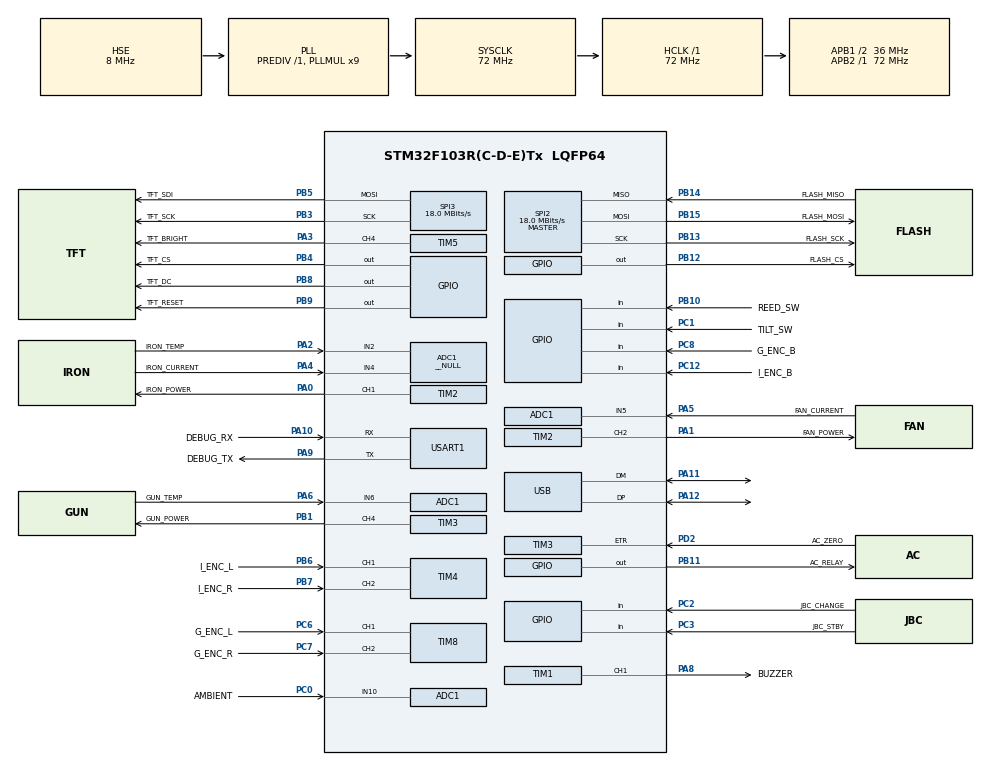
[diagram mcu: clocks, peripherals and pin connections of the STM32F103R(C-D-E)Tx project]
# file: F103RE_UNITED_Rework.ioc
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ADC1.Channel-0\#ChannelRegularConversion=ADC_CHANNEL_4
ADC1.Channel-1\#ChannelRegularConversion=ADC_CHANNEL_5
ADC1.Channel-2\#ChannelRegularConversion=ADC_CHANNEL_2
ADC1.Channel-6\#ChannelRegularConversion=ADC_CHANNEL_6
ADC1.Channel-7\#ChannelRegularConversion=ADC_CHANNEL_10
ADC1.ContinuousConvMode=ENABLE
ADC1.Mode=__NULL
ADC1.NbrOfConversion=5
ADC1.NbrOfConversionFlag=1
ADC1.Rank-0\#ChannelRegularConversion=1
ADC1.Rank-1\#ChannelRegularConversion=2
ADC1.Rank-2\#ChannelRegularConversion=3
ADC1.Rank-6\#ChannelRegularConversion=4
ADC1.Rank-7\#ChannelRegularConversion=5
ADC1.SamplingTime-0\#ChannelRegularConversion=ADC_SAMPLETIME_71CYCLES_5
ADC1.SamplingTime-1\#ChannelRegularConversion=ADC_SAMPLETIME_71CYCLES_5
ADC1.SamplingTime-2\#ChannelRegularConversion=ADC_SAMPLETIME_239CYCLES_5
ADC1.SamplingTime-6\#ChannelRegularConversion=ADC_SAMPLETIME_239CYCLES_5
ADC1.SamplingTime-7\#ChannelRegularConversion=ADC_SAMPLETIME_239CYCLES_5
ADC1.master=1
Dma.ADC1.0.Direction=DMA_PERIPH_TO_MEMORY
Dma.ADC1.0.Instance=DMA1_Channel1
Dma.ADC1.0.MemDataAlignment=DMA_MDATAALIGN_HALFWORD
Dma.ADC1.0.MemInc=DMA_MINC_ENABLE
Dma.ADC1.0.Mode=DMA_NORMAL
Dma.ADC1.0.PeriphDataAlignment=DMA_PDATAALIGN_HALFWORD
Dma.ADC1.0.PeriphInc=DMA_PINC_DISABLE
Dma.ADC1.0.Priority=DMA_PRIORITY_LOW
Dma.Request0=ADC1
Dma.Request1=SPI3_TX
Dma.Request2=TIM3_CH4/UP
Dma.SPI3_TX.1.Direction=DMA_MEMORY_TO_PERIPH
Dma.SPI3_TX.1.Instance=DMA2_Channel2
Dma.SPI3_TX.1.MemDataAlignment=DMA_MDATAALIGN_BYTE
Dma.SPI3_TX.1.MemInc=DMA_MINC_ENABLE
Dma.SPI3_TX.1.Mode=DMA_NORMAL
Dma.SPI3_TX.1.PeriphDataAlignment=DMA_PDATAALIGN_BYTE
Dma.SPI3_TX.1.PeriphInc=DMA_PINC_DISABLE
Dma.SPI3_TX.1.Priority=DMA_PRIORITY_LOW
Dma.TIM3_CH4/UP.2.Direction=DMA_MEMORY_TO_PERIPH
Dma.TIM3_CH4/UP.2.Instance=DMA1_Channel3
Dma.TIM3_CH4/UP.2.MemDataAlignment=DMA_MDATAALIGN_BYTE
Dma.TIM3_CH4/UP.2.MemInc=DMA_MINC_ENABLE
Dma.TIM3_CH4/UP.2.Mode=DMA_CIRCULAR
Dma.TIM3_CH4/UP.2.PeriphDataAlignment=DMA_PDATAALIGN_HALFWORD
Dma.TIM3_CH4/UP.2.PeriphInc=DMA_PINC_DISABLE
Dma.TIM3_CH4/UP.2.Priority=DMA_PRIORITY_LOW
Mcu.Family=STM32F1
Mcu.Name=STM32F103R(C-D-E)Tx
Mcu.Package=LQFP64
NVIC.DMA1_Channel1_IRQn=true\:0\:0\:false\:false\:true\:false\:true\:true
NVIC.DMA1_Channel3_IRQn=true\:0\:0\:false\:false\:true\:false\:true\:true
NVIC.DMA2_Channel2_IRQn=true\:0\:0\:false\:false\:true\:false\:true\:true
NVIC.PriorityGroup=NVIC_PRIORITYGROUP_4
NVIC.TIM2_IRQn=true\:0\:0\:false\:false\:true\:true\:true\:true
NVIC.TIM3_IRQn=true\:0\:0\:false\:false\:true\:true\:true\:true
NVIC.TIM6_IRQn=true\:0\:0\:false\:false\:true\:true\:true\:true
NVIC.USB_LP_CAN1_RX0_IRQn=true\:0\:0\:false\:false\:true\:false\:true\:true
PA0-WKUP.GPIO_Label=IRON_POWER
PA0-WKUP.Signal=S_TIM2_CH1_ETR
PA1.GPIO_Label=FAN_POWER
PA1.Signal=S_TIM2_CH2
PA10.GPIO_Label=DEBUG_RX
PA10.Mode=Asynchronous
PA10.Signal=USART1_RX
PA11.Mode=Device
PA11.Signal=USB_DM
PA12.Mode=Device
PA12.Signal=USB_DP
PA13.Mode=Serial_Wire
PA13.Signal=SYS_JTMS-SWDIO
PA14.Mode=Serial_Wire
PA14.Signal=SYS_JTCK-SWCLK
PA2.GPIO_Label=IRON_TEMP
PA2.Signal=ADCx_IN2
PA3.GPIO_Label=TFT_BRIGHT
PA3.Signal=S_TIM5_CH4
PA4.GPIO_Label=IRON_CURRENT
PA4.Signal=ADCx_IN4
PA5.GPIO_Label=FAN_CURRENT
PA5.Signal=ADCx_IN5
PA6.GPIO_Label=GUN_TEMP
PA6.Signal=ADCx_IN6
PA8.GPIO_Label=BUZZER
PA8.Signal=S_TIM1_CH1
PA9.GPIO_Label=DEBUG_TX
PA9.Mode=Asynchronous
PA9.Signal=USART1_TX
PB1.GPIO_Label=GUN_POWER
PB1.Signal=S_TIM3_CH4
PB10.GPIO_Label=REED_SW
PB10.Signal=GPIO_Input
PB11.GPIO_Label=AC_RELAY
PB11.Signal=GPIO_Output
PB12.GPIO_Label=FLASH_CS
PB12.PinState=GPIO_PIN_SET
PB12.Signal=GPIO_Output
PB13.GPIO_Label=FLASH_SCK
PB13.Mode=Full_Duplex_Master
PB13.Signal=SPI2_SCK
PB14.GPIO_Label=FLASH_MISO
PB14.Mode=Full_Duplex_Master
PB14.Signal=SPI2_MISO
PB15.GPIO_Label=FLASH_MOSI
PB15.Mode=Full_Duplex_Master
PB15.Signal=SPI2_MOSI
PB3.GPIO_Label=TFT_SCK
PB3.Mode=TX_Only_Simplex_Unidirect_Master
PB3.Signal=SPI3_SCK
PB4.GPIO_Label=TFT_CS
PB4.PinState=GPIO_PIN_SET
PB4.Signal=GPIO_Output
PB5.GPIO_Label=TFT_SDI
PB5.Mode=TX_Only_Simplex_Unidirect_Master
PB5.Signal=SPI3_MOSI
PB6.GPIO_Label=I_ENC_L
PB6.Signal=S_TIM4_CH1
PB7.GPIO_Label=I_ENC_R
PB7.Signal=S_TIM4_CH2
PB8.GPIO_Label=TFT_DC
PB8.Signal=GPIO_Output
PB9.GPIO_Label=TFT_RESET
PB9.PinState=GPIO_PIN_SET
PB9.Signal=GPIO_Output
PC0.GPIO_Label=AMBIENT
PC0.Signal=ADCx_IN10
PC1.GPIO_Label=TILT_SW
PC1.Signal=GPIO_Input
PC12.GPIO_Label=I_ENC_B
PC12.Signal=GPIO_Input
PC2.GPIO_Label=JBC_CHANGE
PC2.Signal=GPIO_Input
PC3.GPIO_Label=JBC_STBY
PC3.Signal=GPIO_Input
PC6.GPIO_Label=G_ENC_L
PC6.Signal=S_TIM8_CH1
PC7.GPIO_Label=G_ENC_R
PC7.Signal=S_TIM8_CH2
PC8.GPIO_Label=G_ENC_B
PC8.Signal=GPIO_Input
PD0-OSC_IN.Mode=HSE-External-Oscillator
PD0-OSC_IN.Signal=RCC_OSC_IN
PD1-OSC_OUT.Mode=HSE-External-Oscillator
PD1-OSC_OUT.Signal=RCC_OSC_OUT
PD2.GPIO_Label=AC_ZERO
PD2.Signal=S_TIM3_ETR
ProjectManager.HeapSize=0x200
ProjectManager.StackSize=0x400
ProjectManager.TargetToolchain=STM32CubeIDE
RCC.ADCPresc=RCC_ADCPCLK2_DIV6
RCC.AHBFreq_Value=72000000
RCC.APB1CLKDivider=RCC_HCLK_DIV2
RCC.APB1Freq_Value=36000000
RCC.APB1TimFreq_Value=72000000
RCC.APB2Freq_Value=72000000
RCC.APB2TimFreq_Value=72000000
RCC.HCLKFreq_Value=72000000
RCC.PLLMUL=RCC_PLL_MUL9
RCC.PLLSourceVirtual=RCC_PLLSOURCE_HSE
RCC.SYSCLKFreq_VALUE=72000000
RCC.SYSCLKSource=RCC_SYSCLKSOURCE_PLLCLK
RCC.USBFreq_Value=48000000
RCC.USBPrescaler=RCC_USBCLKSOURCE_PLL_DIV1_5
SH.ADCx_IN10.0=ADC1_IN10,IN10
SH.ADCx_IN2.0=ADC1_IN2,IN2
SH.ADCx_IN4.0=ADC1_IN4,IN4
SH.ADCx_IN5.0=ADC1_IN5,IN5
SH.ADCx_IN6.0=ADC1_IN6,IN6
SH.S_TIM1_CH1.0=TIM1_CH1,PWM Generation1 CH1
SH.S_TIM2_CH1_ETR.0=TIM2_CH1,PWM Generation1 CH1
SH.S_TIM2_CH2.0=TIM2_CH2,PWM Generation2 CH2
SH.S_TIM3_CH4.0=TIM3_CH4,PWM Generation4 CH4
SH.S_TIM3_ETR.0=TIM3_ETR,TriggerSource_ETR
SH.S_TIM4_CH1.0=TIM4_CH1,Encoder_Interface
SH.S_TIM4_CH2.0=TIM4_CH2,Encoder_Interface
SH.S_TIM5_CH4.0=TIM5_CH4,PWM Generation4 CH4
SH.S_TIM8_CH1.0=TIM8_CH1,Encoder_Interface
SH.S_TIM8_CH2.0=TIM8_CH2,Encoder_Interface
SPI2.CalculateBaudRate=18.0 MBits/s
SPI2.Direction=SPI_DIRECTION_2LINES
SPI2.Mode=SPI_MODE_MASTER
SPI2.VirtualType=VM_MASTER
SPI3.CalculateBaudRate=18.0 MBits/s
SPI3.Direction=SPI_DIRECTION_2LINES
SPI3.Mode=SPI_MODE_MASTER
SPI3.VirtualType=VM_MASTER
TIM1.Channel-PWM\ Generation1\ CH1=TIM_CHANNEL_1
TIM1.Prescaler=71
TIM2.Channel-Output\ Compare3\ No\ Output=TIM_CHANNEL_3
TIM2.Channel-Output\ Compare4\ No\ Output=TIM_CHANNEL_4
TIM2.Channel-PWM\ Generation1\ CH1=TIM_CHANNEL_1
TIM2.Channel-PWM\ Generation2\ CH2=TIM_CHANNEL_2
TIM2.Period=1999
TIM2.Prescaler=719
TIM2.Pulse-Output\ Compare3\ No\ Output=1
TIM2.Pulse-Output\ Compare4\ No\ Output=1970
TIM3.Channel-PWM\ Generation4\ CH4=TIM_CHANNEL_4
TIM3.OCMode_PWM-PWM\ Generation4\ CH4=TIM_OCMODE_PWM1
TIM3.Period=255
TIM3.Prescaler=7199
TIM3.Slave_TriggerFilter=7
TIM5.Channel-PWM\ Generation4\ CH4=TIM_CHANNEL_4
TIM5.OCPolarity_4=TIM_OCPOLARITY_LOW
TIM5.Period=255
TIM5.Prescaler=310
TIM5.Pulse-PWM\ Generation4\ CH4=0
TIM6.Prescaler=7199
USART1.VirtualMode=VM_ASYNC
USB_DEVICE.CLASS_NAME_FS=MSC
USB_DEVICE.MSC_MEDIA_PACKET=4096
USB_DEVICE.VirtualMode=Msc
USB_DEVICE.VirtualModeFS=Msc_FS
VP_TIM1_VS_ClockSourceINT.Mode=Internal
VP_TIM2_VS_ClockSourceINT.Mode=Internal
VP_TIM2_VS_no_output3.Mode=Output Compare3 No Output
VP_TIM2_VS_no_output4.Mode=Output Compare4 No Output
VP_TIM3_VS_ClockSourceINT.Mode=Internal
VP_TIM3_VS_ControllerModeReset.Mode=Reset Mode
VP_TIM5_VS_ClockSourceINT.Mode=Internal
VP_TIM6_VS_ClockSourceINT.Mode=Enable_Timer
VP_USB_DEVICE_VS_USB_DEVICE_MSC_FS.Mode=MSC_FS
board=custom

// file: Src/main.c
/* USER CODE BEGIN Header */
/**
  ******************************************************************************
  * @file           : main.c
  * @brief          : Main program body
  ******************************************************************************
  * @attention
  *
  * Copyright (c) 2024 STMicroelectronics.
  * All rights reserved.
  *
  * This software is licensed under terms that can be found in the LICENSE file
  * in the root directory of this software component.
  * If no LICENSE file comes with this software, it is provided AS-IS.
  *
  ******************************************************************************
  */
/* USER CODE END Header */
#include "main.h"
#include "usb_device.h"

/* USER CODE BEGIN Includes */
#include "core.h"

/* USER CODE END Includes */

ADC_HandleTypeDef hadc1;
DMA_HandleTypeDef hdma_adc1;

SPI_HandleTypeDef hspi2;
SPI_HandleTypeDef hspi3;
DMA_HandleTypeDef hdma_spi3_tx;

TIM_HandleTypeDef htim1;
TIM_HandleTypeDef htim2;
TIM_HandleTypeDef htim3;
TIM_HandleTypeDef htim4;
TIM_HandleTypeDef htim5;
TIM_HandleTypeDef htim6;
TIM_HandleTypeDef htim8;
DMA_HandleTypeDef hdma_tim3_ch4_up;

UART_HandleTypeDef huart1;

void SystemClock_Config(void);
static void MX_GPIO_Init(void);
static void MX_DMA_Init(void);
static void MX_ADC1_Init(void);
static void MX_TIM1_Init(void);
static void MX_TIM2_Init(void);
static void MX_TIM3_Init(void);
static void MX_TIM4_Init(void);
static void MX_TIM5_Init(void);
static void MX_TIM8_Init(void);
static void MX_SPI2_Init(void);
static void MX_SPI3_Init(void);
static void MX_USART1_UART_Init(void);
static void MX_TIM6_Init(void);

int main(void)
{

  /* MCU Configuration--------------------------------------------------------*/

  /* Reset of all peripherals, Initializes the Flash interface and the Systick. */
  HAL_Init();

  /* Configure the system clock */
  SystemClock_Config();

  /* Initialize all configured peripherals */
  MX_GPIO_Init();
  MX_DMA_Init();
  MX_USB_DEVICE_Init();
  MX_ADC1_Init();
  MX_TIM1_Init();
  MX_TIM2_Init();
  MX_TIM3_Init();
  MX_TIM4_Init();
  MX_TIM5_Init();
  MX_TIM8_Init();
  MX_SPI2_Init();
  MX_SPI3_Init();
  MX_USART1_UART_Init();
  MX_TIM6_Init();
  /* USER CODE BEGIN 2 */
  HAL_TIM_PWM_Start(&htim5, TIM_CHANNEL_4);						// To Fix bug full backlight at startup; stm32F103ret6 only
  setup();

  /* USER CODE END 2 */

  /* Infinite loop */
  while (1)
  {

    /* USER CODE BEGIN 3 */
	loop();
  }
  /* USER CODE END 3 */
}

void SystemClock_Config(void)
{
  RCC_OscInitTypeDef RCC_OscInitStruct = {0};
  RCC_ClkInitTypeDef RCC_ClkInitStruct = {0};
  RCC_PeriphCLKInitTypeDef PeriphClkInit = {0};

  /** Initializes the RCC Oscillators according to the specified parameters
  * in the RCC_OscInitTypeDef structure.
  */
  RCC_OscInitStruct.OscillatorType = RCC_OSCILLATORTYPE_HSE;
  RCC_OscInitStruct.HSEState = RCC_HSE_ON;
  RCC_OscInitStruct.HSEPredivValue = RCC_HSE_PREDIV_DIV1;
  RCC_OscInitStruct.HSIState = RCC_HSI_ON;
  RCC_OscInitStruct.PLL.PLLState = RCC_PLL_ON;
  RCC_OscInitStruct.PLL.PLLSource = RCC_PLLSOURCE_HSE;
  RCC_OscInitStruct.PLL.PLLMUL = RCC_PLL_MUL9;
  if (HAL_RCC_OscConfig(&RCC_OscInitStruct) != HAL_OK)
  {
    Error_Handler();
  }

  /** Initializes the CPU, AHB and APB buses clocks
  */
  RCC_ClkInitStruct.ClockType = RCC_CLOCKTYPE_HCLK|RCC_CLOCKTYPE_SYSCLK
                              |RCC_CLOCKTYPE_PCLK1|RCC_CLOCKTYPE_PCLK2;
  RCC_ClkInitStruct.SYSCLKSource = RCC_SYSCLKSOURCE_PLLCLK;
  RCC_ClkInitStruct.AHBCLKDivider = RCC_SYSCLK_DIV1;
  RCC_ClkInitStruct.APB1CLKDivider = RCC_HCLK_DIV2;
  RCC_ClkInitStruct.APB2CLKDivider = RCC_HCLK_DIV1;

  if (HAL_RCC_ClockConfig(&RCC_ClkInitStruct, FLASH_LATENCY_2) != HAL_OK)
  {
    Error_Handler();
  }
  PeriphClkInit.PeriphClockSelection = RCC_PERIPHCLK_ADC|RCC_PERIPHCLK_USB;
  PeriphClkInit.AdcClockSelection = RCC_ADCPCLK2_DIV6;
  PeriphClkInit.UsbClockSelection = RCC_USBCLKSOURCE_PLL_DIV1_5;
  if (HAL_RCCEx_PeriphCLKConfig(&PeriphClkInit) != HAL_OK)
  {
    Error_Handler();
  }
}

static void MX_ADC1_Init(void)
{

  ADC_ChannelConfTypeDef sConfig = {0};

  /** Common config
  */
  hadc1.Instance = ADC1;
  hadc1.Init.ScanConvMode = ADC_SCAN_ENABLE;
  hadc1.Init.ContinuousConvMode = ENABLE;
  hadc1.Init.DiscontinuousConvMode = DISABLE;
  hadc1.Init.ExternalTrigConv = ADC_SOFTWARE_START;
  hadc1.Init.DataAlign = ADC_DATAALIGN_RIGHT;
  hadc1.Init.NbrOfConversion = 5;
  if (HAL_ADC_Init(&hadc1) != HAL_OK)
  {
    Error_Handler();
  }

  /** Configure Regular Channel
  */
  sConfig.Channel = ADC_CHANNEL_4;
  sConfig.Rank = ADC_REGULAR_RANK_1;
  sConfig.SamplingTime = ADC_SAMPLETIME_71CYCLES_5;
  if (HAL_ADC_ConfigChannel(&hadc1, &sConfig) != HAL_OK)
  {
    Error_Handler();
  }

  /** Configure Regular Channel
  */
  sConfig.Channel = ADC_CHANNEL_5;
  sConfig.Rank = ADC_REGULAR_RANK_2;
  if (HAL_ADC_ConfigChannel(&hadc1, &sConfig) != HAL_OK)
  {
    Error_Handler();
  }

  /** Configure Regular Channel
  */
  sConfig.Channel = ADC_CHANNEL_2;
  sConfig.Rank = ADC_REGULAR_RANK_3;
  sConfig.SamplingTime = ADC_SAMPLETIME_239CYCLES_5;
  if (HAL_ADC_ConfigChannel(&hadc1, &sConfig) != HAL_OK)
  {
    Error_Handler();
  }

  /** Configure Regular Channel
  */
  sConfig.Channel = ADC_CHANNEL_6;
  sConfig.Rank = ADC_REGULAR_RANK_4;
  if (HAL_ADC_ConfigChannel(&hadc1, &sConfig) != HAL_OK)
  {
    Error_Handler();
  }

  /** Configure Regular Channel
  */
  sConfig.Channel = ADC_CHANNEL_10;
  sConfig.Rank = ADC_REGULAR_RANK_5;
  if (HAL_ADC_ConfigChannel(&hadc1, &sConfig) != HAL_OK)
  {
    Error_Handler();
  }

}

static void MX_SPI2_Init(void)
{

  /* SPI2 parameter configuration*/
  hspi2.Instance = SPI2;
  hspi2.Init.Mode = SPI_MODE_MASTER;
  hspi2.Init.Direction = SPI_DIRECTION_2LINES;
  hspi2.Init.DataSize = SPI_DATASIZE_8BIT;
  hspi2.Init.CLKPolarity = SPI_POLARITY_LOW;
  hspi2.Init.CLKPhase = SPI_PHASE_1EDGE;
  hspi2.Init.NSS = SPI_NSS_SOFT;
  hspi2.Init.BaudRatePrescaler = SPI_BAUDRATEPRESCALER_2;
  hspi2.Init.FirstBit = SPI_FIRSTBIT_MSB;
  hspi2.Init.TIMode = SPI_TIMODE_DISABLE;
  hspi2.Init.CRCCalculation = SPI_CRCCALCULATION_DISABLE;
  hspi2.Init.CRCPolynomial = 10;
  if (HAL_SPI_Init(&hspi2) != HAL_OK)
  {
    Error_Handler();
  }

}

static void MX_SPI3_Init(void)
{

  /* SPI3 parameter configuration*/
  hspi3.Instance = SPI3;
  hspi3.Init.Mode = SPI_MODE_MASTER;
  hspi3.Init.Direction = SPI_DIRECTION_2LINES;
  hspi3.Init.DataSize = SPI_DATASIZE_8BIT;
  hspi3.Init.CLKPolarity = SPI_POLARITY_LOW;
  hspi3.Init.CLKPhase = SPI_PHASE_1EDGE;
  hspi3.Init.NSS = SPI_NSS_SOFT;
  hspi3.Init.BaudRatePrescaler = SPI_BAUDRATEPRESCALER_2;
  hspi3.Init.FirstBit = SPI_FIRSTBIT_MSB;
  hspi3.Init.TIMode = SPI_TIMODE_DISABLE;
  hspi3.Init.CRCCalculation = SPI_CRCCALCULATION_DISABLE;
  hspi3.Init.CRCPolynomial = 10;
  if (HAL_SPI_Init(&hspi3) != HAL_OK)
  {
    Error_Handler();
  }

}

static void MX_TIM1_Init(void)
{

  TIM_ClockConfigTypeDef sClockSourceConfig = {0};
  TIM_MasterConfigTypeDef sMasterConfig = {0};
  TIM_OC_InitTypeDef sConfigOC = {0};
  TIM_BreakDeadTimeConfigTypeDef sBreakDeadTimeConfig = {0};

  htim1.Instance = TIM1;
  htim1.Init.Prescaler = 71;
  htim1.Init.CounterMode = TIM_COUNTERMODE_UP;
  htim1.Init.Period = 65535;
  htim1.Init.ClockDivision = TIM_CLOCKDIVISION_DIV1;
  htim1.Init.RepetitionCounter = 0;
  htim1.Init.AutoReloadPreload = TIM_AUTORELOAD_PRELOAD_DISABLE;
  if (HAL_TIM_Base_Init(&htim1) != HAL_OK)
  {
    Error_Handler();
  }
  sClockSourceConfig.ClockSource = TIM_CLOCKSOURCE_INTERNAL;
  if (HAL_TIM_ConfigClockSource(&htim1, &sClockSourceConfig) != HAL_OK)
  {
    Error_Handler();
  }
  if (HAL_TIM_PWM_Init(&htim1) != HAL_OK)
  {
    Error_Handler();
  }
  sMasterConfig.MasterOutputTrigger = TIM_TRGO_RESET;
  sMasterConfig.MasterSlaveMode = TIM_MASTERSLAVEMODE_DISABLE;
  if (HAL_TIMEx_MasterConfigSynchronization(&htim1, &sMasterConfig) != HAL_OK)
  {
    Error_Handler();
  }
  sConfigOC.OCMode = TIM_OCMODE_PWM1;
  sConfigOC.Pulse = 0;
  sConfigOC.OCPolarity = TIM_OCPOLARITY_HIGH;
  sConfigOC.OCNPolarity = TIM_OCNPOLARITY_HIGH;
  sConfigOC.OCFastMode = TIM_OCFAST_DISABLE;
  sConfigOC.OCIdleState = TIM_OCIDLESTATE_RESET;
  sConfigOC.OCNIdleState = TIM_OCNIDLESTATE_RESET;
  if (HAL_TIM_PWM_ConfigChannel(&htim1, &sConfigOC, TIM_CHANNEL_1) != HAL_OK)
  {
    Error_Handler();
  }
  sBreakDeadTimeConfig.OffStateRunMode = TIM_OSSR_DISABLE;
  sBreakDeadTimeConfig.OffStateIDLEMode = TIM_OSSI_DISABLE;
  sBreakDeadTimeConfig.LockLevel = TIM_LOCKLEVEL_OFF;
  sBreakDeadTimeConfig.DeadTime = 0;
  sBreakDeadTimeConfig.BreakState = TIM_BREAK_DISABLE;
  sBreakDeadTimeConfig.BreakPolarity = TIM_BREAKPOLARITY_HIGH;
  sBreakDeadTimeConfig.AutomaticOutput = TIM_AUTOMATICOUTPUT_DISABLE;
  if (HAL_TIMEx_ConfigBreakDeadTime(&htim1, &sBreakDeadTimeConfig) != HAL_OK)
  {
    Error_Handler();
  }
  HAL_TIM_MspPostInit(&htim1);

}

static void MX_TIM2_Init(void)
{

  TIM_ClockConfigTypeDef sClockSourceConfig = {0};
  TIM_MasterConfigTypeDef sMasterConfig = {0};
  TIM_OC_InitTypeDef sConfigOC = {0};

  htim2.Instance = TIM2;
  htim2.Init.Prescaler = 719;
  htim2.Init.CounterMode = TIM_COUNTERMODE_UP;
  htim2.Init.Period = 1999;
  htim2.Init.ClockDivision = TIM_CLOCKDIVISION_DIV1;
  htim2.Init.AutoReloadPreload = TIM_AUTORELOAD_PRELOAD_DISABLE;
  if (HAL_TIM_Base_Init(&htim2) != HAL_OK)
  {
    Error_Handler();
  }
  sClockSourceConfig.ClockSource = TIM_CLOCKSOURCE_INTERNAL;
  if (HAL_TIM_ConfigClockSource(&htim2, &sClockSourceConfig) != HAL_OK)
  {
    Error_Handler();
  }
  if (HAL_TIM_PWM_Init(&htim2) != HAL_OK)
  {
    Error_Handler();
  }
  if (HAL_TIM_OC_Init(&htim2) != HAL_OK)
  {
    Error_Handler();
  }
  sMasterConfig.MasterOutputTrigger = TIM_TRGO_RESET;
  sMasterConfig.MasterSlaveMode = TIM_MASTERSLAVEMODE_DISABLE;
  if (HAL_TIMEx_MasterConfigSynchronization(&htim2, &sMasterConfig) != HAL_OK)
  {
    Error_Handler();
  }
  sConfigOC.OCMode = TIM_OCMODE_PWM1;
  sConfigOC.Pulse = 0;
  sConfigOC.OCPolarity = TIM_OCPOLARITY_HIGH;
  sConfigOC.OCFastMode = TIM_OCFAST_DISABLE;
  if (HAL_TIM_PWM_ConfigChannel(&htim2, &sConfigOC, TIM_CHANNEL_1) != HAL_OK)
  {
    Error_Handler();
  }
  if (HAL_TIM_PWM_ConfigChannel(&htim2, &sConfigOC, TIM_CHANNEL_2) != HAL_OK)
  {
    Error_Handler();
  }
  sConfigOC.OCMode = TIM_OCMODE_TIMING;
  sConfigOC.Pulse = 1;
  if (HAL_TIM_OC_ConfigChannel(&htim2, &sConfigOC, TIM_CHANNEL_3) != HAL_OK)
  {
    Error_Handler();
  }
  sConfigOC.Pulse = 1970;
  if (HAL_TIM_OC_ConfigChannel(&htim2, &sConfigOC, TIM_CHANNEL_4) != HAL_OK)
  {
    Error_Handler();
  }
  HAL_TIM_MspPostInit(&htim2);

}

static void MX_TIM3_Init(void)
{

  TIM_ClockConfigTypeDef sClockSourceConfig = {0};
  TIM_SlaveConfigTypeDef sSlaveConfig = {0};
  TIM_MasterConfigTypeDef sMasterConfig = {0};
  TIM_OC_InitTypeDef sConfigOC = {0};

  htim3.Instance = TIM3;
  htim3.Init.Prescaler = 7199;
  htim3.Init.CounterMode = TIM_COUNTERMODE_UP;
  htim3.Init.Period = 255;
  htim3.Init.ClockDivision = TIM_CLOCKDIVISION_DIV1;
  htim3.Init.AutoReloadPreload = TIM_AUTORELOAD_PRELOAD_DISABLE;
  if (HAL_TIM_Base_Init(&htim3) != HAL_OK)
  {
    Error_Handler();
  }
  sClockSourceConfig.ClockSource = TIM_CLOCKSOURCE_INTERNAL;
  if (HAL_TIM_ConfigClockSource(&htim3, &sClockSourceConfig) != HAL_OK)
  {
    Error_Handler();
  }
  if (HAL_TIM_PWM_Init(&htim3) != HAL_OK)
  {
    Error_Handler();
  }
  sSlaveConfig.SlaveMode = TIM_SLAVEMODE_RESET;
  sSlaveConfig.InputTrigger = TIM_TS_ETRF;
  sSlaveConfig.TriggerPolarity = TIM_TRIGGERPOLARITY_NONINVERTED;
  sSlaveConfig.TriggerPrescaler = TIM_TRIGGERPRESCALER_DIV1;
  sSlaveConfig.TriggerFilter = 7;
  if (HAL_TIM_SlaveConfigSynchro(&htim3, &sSlaveConfig) != HAL_OK)
  {
    Error_Handler();
  }
  sMasterConfig.MasterOutputTrigger = TIM_TRGO_RESET;
  sMasterConfig.MasterSlaveMode = TIM_MASTERSLAVEMODE_DISABLE;
  if (HAL_TIMEx_MasterConfigSynchronization(&htim3, &sMasterConfig) != HAL_OK)
  {
    Error_Handler();
  }
  sConfigOC.OCMode = TIM_OCMODE_PWM1;
  sConfigOC.Pulse = 0;
  sConfigOC.OCPolarity = TIM_OCPOLARITY_HIGH;
  sConfigOC.OCFastMode = TIM_OCFAST_DISABLE;
  if (HAL_TIM_PWM_ConfigChannel(&htim3, &sConfigOC, TIM_CHANNEL_4) != HAL_OK)
  {
    Error_Handler();
  }
  HAL_TIM_MspPostInit(&htim3);

}

static void MX_TIM4_Init(void)
{

  TIM_Encoder_InitTypeDef sConfig = {0};
  TIM_MasterConfigTypeDef sMasterConfig = {0};

  htim4.Instance = TIM4;
  htim4.Init.Prescaler = 0;
  htim4.Init.CounterMode = TIM_COUNTERMODE_UP;
  htim4.Init.Period = 65535;
  htim4.Init.ClockDivision = TIM_CLOCKDIVISION_DIV1;
  htim4.Init.AutoReloadPreload = TIM_AUTORELOAD_PRELOAD_DISABLE;
  sConfig.EncoderMode = TIM_ENCODERMODE_TI1;
  sConfig.IC1Polarity = TIM_ICPOLARITY_RISING;
  sConfig.IC1Selection = TIM_ICSELECTION_DIRECTTI;
  sConfig.IC1Prescaler = TIM_ICPSC_DIV1;
  sConfig.IC1Filter = 0;
  sConfig.IC2Polarity = TIM_ICPOLARITY_RISING;
  sConfig.IC2Selection = TIM_ICSELECTION_DIRECTTI;
  sConfig.IC2Prescaler = TIM_ICPSC_DIV1;
  sConfig.IC2Filter = 0;
  if (HAL_TIM_Encoder_Init(&htim4, &sConfig) != HAL_OK)
  {
    Error_Handler();
  }
  sMasterConfig.MasterOutputTrigger = TIM_TRGO_RESET;
  sMasterConfig.MasterSlaveMode = TIM_MASTERSLAVEMODE_DISABLE;
  if (HAL_TIMEx_MasterConfigSynchronization(&htim4, &sMasterConfig) != HAL_OK)
  {
    Error_Handler();
  }

}

static void MX_TIM5_Init(void)
{

  TIM_ClockConfigTypeDef sClockSourceConfig = {0};
  TIM_MasterConfigTypeDef sMasterConfig = {0};
  TIM_OC_InitTypeDef sConfigOC = {0};

  htim5.Instance = TIM5;
  htim5.Init.Prescaler = 310;
  htim5.Init.CounterMode = TIM_COUNTERMODE_UP;
  htim5.Init.Period = 255;
  htim5.Init.ClockDivision = TIM_CLOCKDIVISION_DIV1;
  htim5.Init.AutoReloadPreload = TIM_AUTORELOAD_PRELOAD_DISABLE;
  if (HAL_TIM_Base_Init(&htim5) != HAL_OK)
  {
    Error_Handler();
  }
  sClockSourceConfig.ClockSource = TIM_CLOCKSOURCE_INTERNAL;
  if (HAL_TIM_ConfigClockSource(&htim5, &sClockSourceConfig) != HAL_OK)
  {
    Error_Handler();
  }
  if (HAL_TIM_PWM_Init(&htim5) != HAL_OK)
  {
    Error_Handler();
  }
  sMasterConfig.MasterOutputTrigger = TIM_TRGO_RESET;
  sMasterConfig.MasterSlaveMode = TIM_MASTERSLAVEMODE_DISABLE;
  if (HAL_TIMEx_MasterConfigSynchronization(&htim5, &sMasterConfig) != HAL_OK)
  {
    Error_Handler();
  }
  sConfigOC.OCMode = TIM_OCMODE_PWM1;
  sConfigOC.Pulse = 0;
  sConfigOC.OCPolarity = TIM_OCPOLARITY_LOW;
  sConfigOC.OCFastMode = TIM_OCFAST_DISABLE;
  if (HAL_TIM_PWM_ConfigChannel(&htim5, &sConfigOC, TIM_CHANNEL_4) != HAL_OK)
  {
    Error_Handler();
  }
  HAL_TIM_MspPostInit(&htim5);

}

static void MX_TIM6_Init(void)
{

  TIM_MasterConfigTypeDef sMasterConfig = {0};

  htim6.Instance = TIM6;
  htim6.Init.Prescaler = 7199;
  htim6.Init.CounterMode = TIM_COUNTERMODE_UP;
  htim6.Init.Period = 65535;
  htim6.Init.AutoReloadPreload = TIM_AUTORELOAD_PRELOAD_DISABLE;
  if (HAL_TIM_Base_Init(&htim6) != HAL_OK)
  {
    Error_Handler();
  }
  sMasterConfig.MasterOutputTrigger = TIM_TRGO_RESET;
  sMasterConfig.MasterSlaveMode = TIM_MASTERSLAVEMODE_DISABLE;
  if (HAL_TIMEx_MasterConfigSynchronization(&htim6, &sMasterConfig) != HAL_OK)
  {
    Error_Handler();
  }

}

static void MX_TIM8_Init(void)
{

  TIM_Encoder_InitTypeDef sConfig = {0};
  TIM_MasterConfigTypeDef sMasterConfig = {0};

  htim8.Instance = TIM8;
  htim8.Init.Prescaler = 0;
  htim8.Init.CounterMode = TIM_COUNTERMODE_UP;
  htim8.Init.Period = 65535;
  htim8.Init.ClockDivision = TIM_CLOCKDIVISION_DIV1;
  htim8.Init.RepetitionCounter = 0;
  htim8.Init.AutoReloadPreload = TIM_AUTORELOAD_PRELOAD_DISABLE;
  sConfig.EncoderMode = TIM_ENCODERMODE_TI1;
  sConfig.IC1Polarity = TIM_ICPOLARITY_RISING;
  sConfig.IC1Selection = TIM_ICSELECTION_DIRECTTI;
  sConfig.IC1Prescaler = TIM_ICPSC_DIV1;
  sConfig.IC1Filter = 0;
  sConfig.IC2Polarity = TIM_ICPOLARITY_RISING;
  sConfig.IC2Selection = TIM_ICSELECTION_DIRECTTI;
  sConfig.IC2Prescaler = TIM_ICPSC_DIV1;
  sConfig.IC2Filter = 0;
  if (HAL_TIM_Encoder_Init(&htim8, &sConfig) != HAL_OK)
  {
    Error_Handler();
  }
  sMasterConfig.MasterOutputTrigger = TIM_TRGO_RESET;
  sMasterConfig.MasterSlaveMode = TIM_MASTERSLAVEMODE_DISABLE;
  if (HAL_TIMEx_MasterConfigSynchronization(&htim8, &sMasterConfig) != HAL_OK)
  {
    Error_Handler();
  }

}

static void MX_USART1_UART_Init(void)
{

  huart1.Instance = USART1;
  huart1.Init.BaudRate = 115200;
  huart1.Init.WordLength = UART_WORDLENGTH_8B;
  huart1.Init.StopBits = UART_STOPBITS_1;
  huart1.Init.Parity = UART_PARITY_NONE;
  huart1.Init.Mode = UART_MODE_TX_RX;
  huart1.Init.HwFlowCtl = UART_HWCONTROL_NONE;
  huart1.Init.OverSampling = UART_OVERSAMPLING_16;
  if (HAL_UART_Init(&huart1) != HAL_OK)
  {
    Error_Handler();
  }

}

static void MX_DMA_Init(void)
{

  /* DMA controller clock enable */
  __HAL_RCC_DMA1_CLK_ENABLE();
  __HAL_RCC_DMA2_CLK_ENABLE();

  /* DMA interrupt init */
  /* DMA1_Channel1_IRQn interrupt configuration */
  HAL_NVIC_SetPriority(DMA1_Channel1_IRQn, 0, 0);
  HAL_NVIC_EnableIRQ(DMA1_Channel1_IRQn);
  /* DMA1_Channel3_IRQn interrupt configuration */
  HAL_NVIC_SetPriority(DMA1_Channel3_IRQn, 0, 0);
  HAL_NVIC_EnableIRQ(DMA1_Channel3_IRQn);
  /* DMA2_Channel2_IRQn interrupt configuration */
  HAL_NVIC_SetPriority(DMA2_Channel2_IRQn, 0, 0);
  HAL_NVIC_EnableIRQ(DMA2_Channel2_IRQn);

}

static void MX_GPIO_Init(void)
{
  GPIO_InitTypeDef GPIO_InitStruct = {0};

  /* GPIO Ports Clock Enable */
  __HAL_RCC_GPIOD_CLK_ENABLE();
  __HAL_RCC_GPIOC_CLK_ENABLE();
  __HAL_RCC_GPIOA_CLK_ENABLE();
  __HAL_RCC_GPIOB_CLK_ENABLE();

  /*Configure GPIO pin Output Level */
  HAL_GPIO_WritePin(GPIOB, AC_RELAY_Pin|TFT_DC_Pin, GPIO_PIN_RESET);

  /*Configure GPIO pin Output Level */
  HAL_GPIO_WritePin(GPIOB, FLASH_CS_Pin|TFT_CS_Pin|TFT_RESET_Pin, GPIO_PIN_SET);

  /*Configure GPIO pins : TILT_SW_Pin JBC_CHANGE_Pin JBC_STBY_Pin G_ENC_B_Pin
                           I_ENC_B_Pin */
  GPIO_InitStruct.Pin = TILT_SW_Pin|JBC_CHANGE_Pin|JBC_STBY_Pin|G_ENC_B_Pin
                          |I_ENC_B_Pin;
  GPIO_InitStruct.Mode = GPIO_MODE_INPUT;
  GPIO_InitStruct.Pull = GPIO_NOPULL;
  HAL_GPIO_Init(GPIOC, &GPIO_InitStruct);

  /*Configure GPIO pin : REED_SW_Pin */
  GPIO_InitStruct.Pin = REED_SW_Pin;
  GPIO_InitStruct.Mode = GPIO_MODE_INPUT;
  GPIO_InitStruct.Pull = GPIO_NOPULL;
  HAL_GPIO_Init(REED_SW_GPIO_Port, &GPIO_InitStruct);

  /*Configure GPIO pins : AC_RELAY_Pin FLASH_CS_Pin TFT_CS_Pin TFT_DC_Pin
                           TFT_RESET_Pin */
  GPIO_InitStruct.Pin = AC_RELAY_Pin|FLASH_CS_Pin|TFT_CS_Pin|TFT_DC_Pin
                          |TFT_RESET_Pin;
  GPIO_InitStruct.Mode = GPIO_MODE_OUTPUT_PP;
  GPIO_InitStruct.Pull = GPIO_NOPULL;
  GPIO_InitStruct.Speed = GPIO_SPEED_FREQ_LOW;
  HAL_GPIO_Init(GPIOB, &GPIO_InitStruct);

}

void Error_Handler(void)
{
  __disable_irq();
  while (1)
  {
  }
}
